VERSION "edgeplant-can1"

NS_ :

BS_:

BU_: ECU

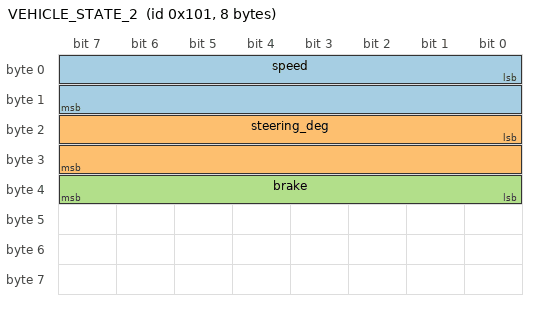
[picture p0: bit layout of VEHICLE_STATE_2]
BO_ 257 VEHICLE_STATE_2: 8 ECU
 SG_ speed : 0|16@1+ (0.01,0) [0|655.35] "km/h" ECU
 SG_ steering_deg : 16|16@1- (0.1,0) [-3276.8|3276.7] "deg" ECU
 SG_ brake : 32|8@1+ (0.4,0) [0|100] "%" ECU

BO_ 258 CONTROL_CMD_2: 8 ECU
 SG_ ControlCommand : 0|1@1+ (1,0) [0|1] "" ECU
 SG_ ControlValue : 8|16@1- (0.1,0) [-3276.8|3276.7] "" ECU
